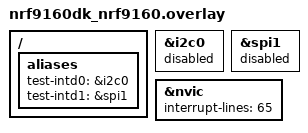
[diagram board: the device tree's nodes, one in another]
/*
 * Copyright (c) 2024 Bjarki Arge Andreasen
 *
 * SPDX-License-Identifier: Apache-2.0
 */

/ {
	aliases {
		test-intd0 = &i2c0;
		test-intd1 = &spi1;
	};
};

&i2c0 {
	status = "reserved";
};

&spi1 {
	status = "reserved";
};

&nvic {
	interrupt-lines = <65>;
};
